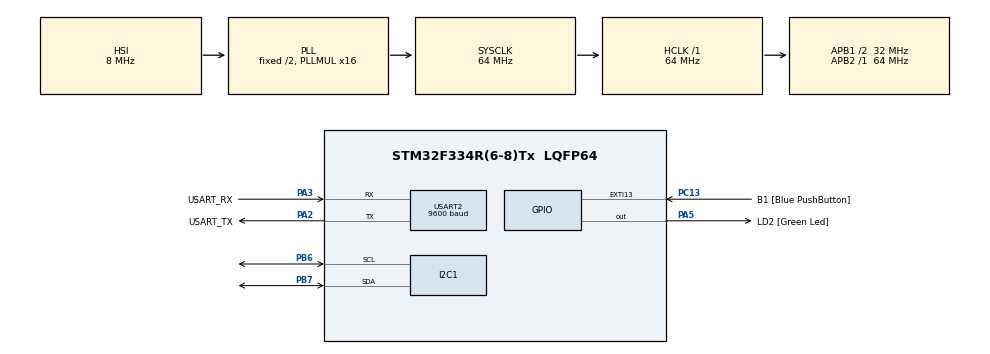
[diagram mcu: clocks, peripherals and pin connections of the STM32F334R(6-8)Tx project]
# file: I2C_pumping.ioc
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Mcu.Family=STM32F3
Mcu.Name=STM32F334R(6-8)Tx
Mcu.Package=LQFP64
NVIC.PriorityGroup=NVIC_PRIORITYGROUP_0
PA13.GPIO_Label=TMS
PA13.Mode=Serial_Wire
PA13.Signal=SYS_JTMS-SWDIO
PA14.GPIO_Label=TCK
PA14.Mode=Serial_Wire
PA14.Signal=SYS_JTCK-SWCLK
PA2.GPIO_Label=USART_TX
PA2.Mode=Asynchronous
PA2.Signal=USART2_TX
PA3.GPIO_Label=USART_RX
PA3.Mode=Asynchronous
PA3.Signal=USART2_RX
PA5.GPIO_Label=LD2 [Green Led]
PA5.Signal=GPIO_Output
PB3.GPIO_Label=SWO
PB3.Signal=SYS_JTDO-TRACESWO
PB6.GPIO_PuPdOD=GPIO_NOPULL
PB6.Mode=I2C
PB6.Signal=I2C1_SCL
PB7.GPIO_PuPdOD=GPIO_NOPULL
PB7.Mode=I2C
PB7.Signal=I2C1_SDA
PC13.GPIO_Label=B1 [Blue PushButton]
PC13.GPIO_ModeDefaultEXTI=GPIO_MODE_IT_FALLING
PC13.Signal=GPXTI13
PC14\ /\ OSC32_IN.Mode=LSE-External-Oscillator
PC14\ /\ OSC32_IN.Signal=RCC_OSC32_IN
PC15\ /\ OSC32_OUT.GPIO_Label=RCC_OSC32_OUT
PC15\ /\ OSC32_OUT.Mode=LSE-External-Oscillator
PC15\ /\ OSC32_OUT.Signal=RCC_OSC32_OUT
PF0\ /\ OSC_IN.Mode=HSE-External-Clock-Source
PF0\ /\ OSC_IN.Signal=RCC_OSC_IN
PF1\ /\ OSC_OUT.Signal=RCC_OSC_OUT
ProjectManager.HeapSize=0x200
ProjectManager.StackSize=0x400
ProjectManager.TargetToolchain=TrueSTUDIO
RCC.AHBFreq_Value=64000000
RCC.APB1CLKDivider=RCC_HCLK_DIV2
RCC.APB1Freq_Value=32000000
RCC.APB1TimFreq_Value=64000000
RCC.APB2Freq_Value=64000000
RCC.APB2TimFreq_Value=64000000
RCC.CortexFreq_Value=64000000
RCC.FLatency-AdvancedSettings=FLASH_LATENCY_2
RCC.HCLKFreq_Value=64000000
RCC.HSE_VALUE=8000000
RCC.HSI_VALUE=8000000
RCC.PLLMUL=RCC_PLL_MUL16
RCC.SYSCLKFreq_VALUE=64000000
RCC.SYSCLKSourceVirtual=RCC_SYSCLKSOURCE_PLLCLK
USART2.BaudRate=9600
USART2.VirtualMode-Asynchronous=VM_ASYNC
USART2.WordLength=WORDLENGTH_8B
board=NUCLEO-F334R8

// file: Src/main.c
/*
 *  	Created on: Feb 24, 2018
 *      Author: Ed Yoshi Hirata
 *      UCSC ASF Group
 */
#include "main.h"
#include "stm32f3xx_hal.h"
#include "I2C_Control.h"
#include "SPS01_control.h"
#include "Valves_4VM01.h"
#include <stdlib.h>

I2C_HandleTypeDef hi2c1;
UART_HandleTypeDef huart2;

/* USER CODE BEGIN PV */
int __io_putchar(int ch) {

	HAL_UART_Transmit(&huart2, (uint8_t *) &ch, 1, 0xFFFF);
	return ch;
}

int _write(int file, char *ptr, int len) {
	int DataIdx;
	for (DataIdx = 0; DataIdx < len; DataIdx++) {
		__io_putchar(*ptr++);
	}
	return len;
}
/* USER CODE END PV */

void SystemClock_Config(void);
static void MX_GPIO_Init(void);
static void MX_USART2_UART_Init(void);
static void MX_I2C1_Init(void);

typedef enum FSM_STATES {
	INIT, FIND_DEVS, INIT_DEV, DONE
} FSM_STATE;

FSM_STATE state = FIND_DEVS;

int main(void) {
	/* MCU Configuration----------------------------------------------------------*/

	/* Reset of all peripherals, Initializes the Flash interface and the Systick. */
	HAL_Init();
	/* Configure the system clock */
	SystemClock_Config();
	/* Initialize all configured peripherals */
	MX_GPIO_Init();
	MX_USART2_UART_Init();
	MX_I2C1_Init();
	uint8_t i = 0, numDev = 0;
	volatile uint8_t foundAddresses[128];

//			foundAddresses[0] = 255; //255 refers to a end of array condition

	/* Infinite loop */
	/* USER CODE BEGIN WHILE */
	while (1) {
		while (1) {
//			printf("start\n");
			SPS01_Init(&hi2c1, 35);
			SPS01_Status(&hi2c1, 35);
			Valve_Position(&hi2c1, 14, 2, 2, 3, 3);
			SPS01_SetSpeed(&hi2c1, 35, 200);
			SPS01_SetVolume(&hi2c1, 35, 50);
			Valve_Position(&hi2c1, 14, 2, 2, 2, 1);
			SPS01_SetSpeed(&hi2c1, 35, 100);
			SPS01_SetVolume(&hi2c1, 35, 0);

			while (1)
				;
		}
		switch (state) {
		case INIT:
			break;
		case FIND_DEVS:
			printf("SEARCHING  DEVICE ADDRESS: %i  DEVICE FOUND:", i << 1);
			if (HAL_I2C_IsDeviceReady(&hi2c1, i << 1, 10, 1000) == HAL_OK) {
				foundAddresses[numDev] = i << 1; //save the address
				printf("YES\n");
				numDev++;
				foundAddresses[numDev] = 255; //
			} else
				printf("NO\n");

			HAL_Delay(100);
			i++;
			if ((i << 1) > 128)
				state = INIT_DEV;
			break;
		case INIT_DEV:
			for (int j = 0; j < numDev; j++)
				printf("Devise found: %i\n", foundAddresses[j] >> 1);
			if (numDev > 0) {
				for (int j = 0; j < numDev; j++) {
					printf("Device on address %i\n contacting device......\n", foundAddresses[j]);

					//HAL_I2C_Mem_Read(&hi2c2, foundAddresses[j], DEV_ID_COMMAND, I2C_MEMADD_SIZE_8BIT, pData, 6, 1000);
					//printf("found dev info : %x, %x, %x \n", pData[0], pData[1], pData[2]);

				}
				state = DONE;

			} else {
				printf("NO DEVICES FOUND, retrying.....\n");
				state = FIND_DEVS;
				i = 0;
			}
			break;
		case DONE:
			printf("\nCOMPLETED\n going to sleep\n");
			while (1)
				;
			break;

		}

	}

}
void SystemClock_Config(void) {

	RCC_OscInitTypeDef RCC_OscInitStruct;
	RCC_ClkInitTypeDef RCC_ClkInitStruct;
	RCC_PeriphCLKInitTypeDef PeriphClkInit;

	/**Initializes the CPU, AHB and APB busses clocks
	 */
	RCC_OscInitStruct.OscillatorType = RCC_OSCILLATORTYPE_HSI;
	RCC_OscInitStruct.HSIState = RCC_HSI_ON;
	RCC_OscInitStruct.HSICalibrationValue = 16;
	RCC_OscInitStruct.PLL.PLLState = RCC_PLL_ON;
	RCC_OscInitStruct.PLL.PLLSource = RCC_PLLSOURCE_HSI;
	RCC_OscInitStruct.PLL.PLLMUL = RCC_PLL_MUL16;
	if (HAL_RCC_OscConfig(&RCC_OscInitStruct) != HAL_OK) {
		_Error_Handler(__FILE__, __LINE__);
	}

	/**Initializes the CPU, AHB and APB busses clocks
	 */
	RCC_ClkInitStruct.ClockType = RCC_CLOCKTYPE_HCLK | RCC_CLOCKTYPE_SYSCLK | RCC_CLOCKTYPE_PCLK1
			| RCC_CLOCKTYPE_PCLK2;
	RCC_ClkInitStruct.SYSCLKSource = RCC_SYSCLKSOURCE_PLLCLK;
	RCC_ClkInitStruct.AHBCLKDivider = RCC_SYSCLK_DIV1;
	RCC_ClkInitStruct.APB1CLKDivider = RCC_HCLK_DIV2;
	RCC_ClkInitStruct.APB2CLKDivider = RCC_HCLK_DIV1;

	if (HAL_RCC_ClockConfig(&RCC_ClkInitStruct, FLASH_LATENCY_2) != HAL_OK) {
		_Error_Handler(__FILE__, __LINE__);
	}

	PeriphClkInit.PeriphClockSelection = RCC_PERIPHCLK_I2C1;
	PeriphClkInit.I2c1ClockSelection = RCC_I2C1CLKSOURCE_HSI;
	if (HAL_RCCEx_PeriphCLKConfig(&PeriphClkInit) != HAL_OK) {
		_Error_Handler(__FILE__, __LINE__);
	}

	/**Configure the Systick interrupt time
	 */
	HAL_SYSTICK_Config(HAL_RCC_GetHCLKFreq() / 1000);

	/**Configure the Systick
	 */
	HAL_SYSTICK_CLKSourceConfig(SYSTICK_CLKSOURCE_HCLK);

	/* SysTick_IRQn interrupt configuration */
	HAL_NVIC_SetPriority(SysTick_IRQn, 0, 0);
}

/* I2C1 init function */
static void MX_I2C1_Init(void) {

	hi2c1.Instance = I2C1;
	hi2c1.Init.Timing = 0x2000090E;
	hi2c1.Init.OwnAddress1 = 0;
	hi2c1.Init.AddressingMode = I2C_ADDRESSINGMODE_7BIT;
	hi2c1.Init.DualAddressMode = I2C_DUALADDRESS_DISABLE;
	hi2c1.Init.OwnAddress2 = 0;
	hi2c1.Init.OwnAddress2Masks = I2C_OA2_NOMASK;
	hi2c1.Init.GeneralCallMode = I2C_GENERALCALL_DISABLE;
	hi2c1.Init.NoStretchMode = I2C_NOSTRETCH_DISABLE;
	if (HAL_I2C_Init(&hi2c1) != HAL_OK) {
		_Error_Handler(__FILE__, __LINE__);
	}

	/**Configure Analogue filter
	 */
	if (HAL_I2CEx_ConfigAnalogFilter(&hi2c1, I2C_ANALOGFILTER_ENABLE) != HAL_OK) {
		_Error_Handler(__FILE__, __LINE__);
	}

	/**Configure Digital filter
	 */
	if (HAL_I2CEx_ConfigDigitalFilter(&hi2c1, 0) != HAL_OK) {
		_Error_Handler(__FILE__, __LINE__);
	}

}

/* USART2 init function */
static void MX_USART2_UART_Init(void) {

	huart2.Instance = USART2;
	huart2.Init.BaudRate = 9600;
	huart2.Init.WordLength = UART_WORDLENGTH_8B;
	huart2.Init.StopBits = UART_STOPBITS_1;
	huart2.Init.Parity = UART_PARITY_NONE;
	huart2.Init.Mode = UART_MODE_TX_RX;
	huart2.Init.HwFlowCtl = UART_HWCONTROL_NONE;
	huart2.Init.OverSampling = UART_OVERSAMPLING_16;
	huart2.Init.OneBitSampling = UART_ONE_BIT_SAMPLE_DISABLE;
	huart2.AdvancedInit.AdvFeatureInit = UART_ADVFEATURE_NO_INIT;
	if (HAL_UART_Init(&huart2) != HAL_OK) {
		_Error_Handler(__FILE__, __LINE__);
	}

}

/** Configure pins as
 * Analog
 * Input
 * Output
 * EVENT_OUT
 * EXTI
 */
static void MX_GPIO_Init(void) {

	GPIO_InitTypeDef GPIO_InitStruct;

	/* GPIO Ports Clock Enable */
	__HAL_RCC_GPIOC_CLK_ENABLE()
	;
	__HAL_RCC_GPIOF_CLK_ENABLE()
	;
	__HAL_RCC_GPIOA_CLK_ENABLE()
	;
	__HAL_RCC_GPIOB_CLK_ENABLE()
	;

	/*Configure GPIO pin Output Level */
	HAL_GPIO_WritePin(LD2_GPIO_Port, LD2_Pin, GPIO_PIN_RESET);

	/*Configure GPIO pin : B1_Pin */
	GPIO_InitStruct.Pin = B1_Pin;
	GPIO_InitStruct.Mode = GPIO_MODE_IT_FALLING;
	GPIO_InitStruct.Pull = GPIO_NOPULL;
	HAL_GPIO_Init(B1_GPIO_Port, &GPIO_InitStruct);

	/*Configure GPIO pin : LD2_Pin */
	GPIO_InitStruct.Pin = LD2_Pin;
	GPIO_InitStruct.Mode = GPIO_MODE_OUTPUT_PP;
	GPIO_InitStruct.Pull = GPIO_NOPULL;
	GPIO_InitStruct.Speed = GPIO_SPEED_FREQ_LOW;
	HAL_GPIO_Init(LD2_GPIO_Port, &GPIO_InitStruct);

}

void _Error_Handler(char *file, int line) {
	while (1) {
	}
}

/************************ (C) COPYRIGHT STMicroelectronics *****END OF FILE****/
